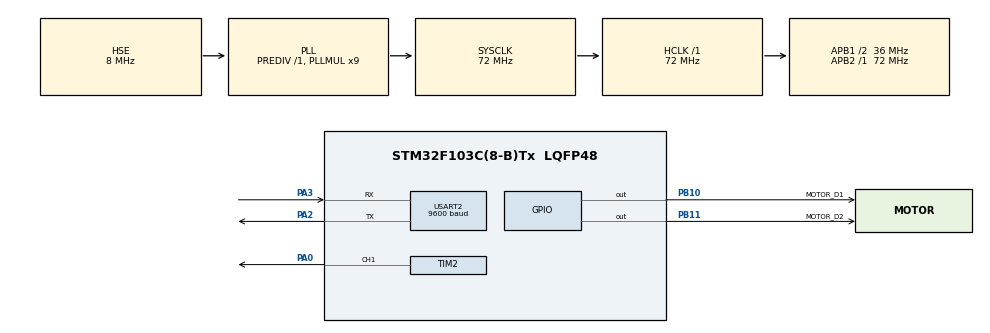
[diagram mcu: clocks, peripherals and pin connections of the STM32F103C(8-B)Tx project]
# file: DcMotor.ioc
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FREERTOS.Tasks01=UART,24,128,UART_T,Default,NULL,Dynamic,NULL,NULL;ADCRead,8,128,ADCRead_T,Default,NULL,Dynamic,NULL,NULL;Motor,10,128,Motor_T,Default,NULL,Dynamic,NULL,NULL
Mcu.Family=STM32F1
Mcu.Name=STM32F103C(8-B)Tx
Mcu.Package=LQFP48
NVIC.PriorityGroup=NVIC_PRIORITYGROUP_4
NVIC.TIM1_UP_IRQn=true\:15\:0\:false\:false\:true\:false\:false\:true\:true
NVIC.TimeBase=TIM1_UP_IRQn
NVIC.TimeBaseIP=TIM1
PA0-WKUP.Signal=S_TIM2_CH1_ETR
PA13.Mode=Serial_Wire
PA13.Signal=SYS_JTMS-SWDIO
PA14.Mode=Serial_Wire
PA14.Signal=SYS_JTCK-SWCLK
PA2.Mode=Asynchronous
PA2.Signal=USART2_TX
PA3.Mode=Asynchronous
PA3.Signal=USART2_RX
PB10.GPIO_Label=MOTOR_D1
PB10.Signal=GPIO_Output
PB11.GPIO_Label=MOTOR_D2
PB11.Signal=GPIO_Output
PD0-OSC_IN.Mode=HSE-External-Oscillator
PD0-OSC_IN.Signal=RCC_OSC_IN
PD1-OSC_OUT.Mode=HSE-External-Oscillator
PD1-OSC_OUT.Signal=RCC_OSC_OUT
ProjectManager.HeapSize=0x200
ProjectManager.StackSize=0x400
ProjectManager.TargetToolchain=STM32CubeIDE
RCC.AHBFreq_Value=72000000
RCC.APB1CLKDivider=RCC_HCLK_DIV2
RCC.APB1Freq_Value=36000000
RCC.APB1TimFreq_Value=72000000
RCC.APB2Freq_Value=72000000
RCC.APB2TimFreq_Value=72000000
RCC.HCLKFreq_Value=72000000
RCC.PLLMUL=RCC_PLL_MUL9
RCC.PLLSourceVirtual=RCC_PLLSOURCE_HSE
RCC.SYSCLKFreq_VALUE=72000000
RCC.SYSCLKSource=RCC_SYSCLKSOURCE_PLLCLK
RCC.USBFreq_Value=72000000
SH.S_TIM2_CH1_ETR.0=TIM2_CH1,PWM Generation1 CH1
TIM2.Channel-PWM\ Generation1\ CH1=TIM_CHANNEL_1
TIM2.Period=100-1
TIM2.Prescaler=72-1
USART2.BaudRate=9600
USART2.VirtualMode=VM_ASYNC
VP_FREERTOS_VS_CMSIS_V2.Mode=CMSIS_V2
VP_SYS_VS_tim1.Mode=TIM1
VP_TIM2_VS_ClockSourceINT.Mode=Internal
board=custom

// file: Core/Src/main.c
/* USER CODE BEGIN Header */
/**
  ******************************************************************************
  * @file           : main.c
  * @brief          : Main program body
  ******************************************************************************
  * @attention
  *
  * Copyright (c) 2024 STMicroelectronics.
  * All rights reserved.
  *
  * This software is licensed under terms that can be found in the LICENSE file
  * in the root directory of this software component.
  * If no LICENSE file comes with this software, it is provided AS-IS.
  *
  ******************************************************************************
  */
/* USER CODE END Header */
#include "main.h"
#include "cmsis_os.h"
#include "tim.h"
#include "usart.h"
#include "gpio.h"

void SystemClock_Config(void);
void MX_FREERTOS_Init(void);

int main(void)
{

  /* MCU Configuration--------------------------------------------------------*/

  /* Reset of all peripherals, Initializes the Flash interface and the Systick. */
  HAL_Init();

  /* Configure the system clock */
  SystemClock_Config();

  /* Initialize all configured peripherals */
  MX_GPIO_Init();
  MX_USART2_UART_Init();
  MX_TIM2_Init();
  /* USER CODE BEGIN 2 */
  /*Start the timer */
   TIM2->CCR1 = 70;
    HAL_TIM_PWM_Start(&htim2,TIM_CHANNEL_1);

  /* USER CODE END 2 */

  /* Init scheduler */
  osKernelInitialize();

  /* Call init function for freertos objects (in cmsis_os2.c) */
  MX_FREERTOS_Init();

  /* Start scheduler */
  osKernelStart();

  /* We should never get here as control is now taken by the scheduler */

  /* Infinite loop */
  while (1)
  {

  }
}

void SystemClock_Config(void)
{
  RCC_OscInitTypeDef RCC_OscInitStruct = {0};
  RCC_ClkInitTypeDef RCC_ClkInitStruct = {0};

  /** Initializes the RCC Oscillators according to the specified parameters
  * in the RCC_OscInitTypeDef structure.
  */
  RCC_OscInitStruct.OscillatorType = RCC_OSCILLATORTYPE_HSE;
  RCC_OscInitStruct.HSEState = RCC_HSE_ON;
  RCC_OscInitStruct.HSEPredivValue = RCC_HSE_PREDIV_DIV1;
  RCC_OscInitStruct.HSIState = RCC_HSI_ON;
  RCC_OscInitStruct.PLL.PLLState = RCC_PLL_ON;
  RCC_OscInitStruct.PLL.PLLSource = RCC_PLLSOURCE_HSE;
  RCC_OscInitStruct.PLL.PLLMUL = RCC_PLL_MUL9;
  if (HAL_RCC_OscConfig(&RCC_OscInitStruct) != HAL_OK)
  {
    Error_Handler();
  }

  /** Initializes the CPU, AHB and APB buses clocks
  */
  RCC_ClkInitStruct.ClockType = RCC_CLOCKTYPE_HCLK|RCC_CLOCKTYPE_SYSCLK
                              |RCC_CLOCKTYPE_PCLK1|RCC_CLOCKTYPE_PCLK2;
  RCC_ClkInitStruct.SYSCLKSource = RCC_SYSCLKSOURCE_PLLCLK;
  RCC_ClkInitStruct.AHBCLKDivider = RCC_SYSCLK_DIV1;
  RCC_ClkInitStruct.APB1CLKDivider = RCC_HCLK_DIV2;
  RCC_ClkInitStruct.APB2CLKDivider = RCC_HCLK_DIV1;

  if (HAL_RCC_ClockConfig(&RCC_ClkInitStruct, FLASH_LATENCY_2) != HAL_OK)
  {
    Error_Handler();
  }
}

void HAL_TIM_PeriodElapsedCallback(TIM_HandleTypeDef *htim)
{
  if (htim->Instance == TIM1) {
    HAL_IncTick();
  }
}

void Error_Handler(void)
{
  __disable_irq();
  while (1)
  {
  }
}

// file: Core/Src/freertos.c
/* USER CODE BEGIN Header */
/**
  ******************************************************************************
  * File Name          : freertos.c
  * Description        : Code for freertos applications
  ******************************************************************************
  * @attention
  *
  * Copyright (c) 2024 STMicroelectronics.
  * All rights reserved.
  *
  * This software is licensed under terms that can be found in the LICENSE file
  * in the root directory of this software component.
  * If no LICENSE file comes with this software, it is provided AS-IS.
  *
  ******************************************************************************
  */
/* USER CODE END Header */

#include "FreeRTOS.h"
#include "task.h"
#include "main.h"
#include "cmsis_os.h"

/* USER CODE BEGIN Includes */
#include "Motor.h"
/* USER CODE END Includes */

/* Definitions for UART */
osThreadId_t UARTHandle;
const osThreadAttr_t UART_attributes = {
  .name = "UART",
  .stack_size = 128 * 4,
  .priority = (osPriority_t) osPriorityNormal,
};
/* Definitions for ADCRead */
osThreadId_t ADCReadHandle;
const osThreadAttr_t ADCRead_attributes = {
  .name = "ADCRead",
  .stack_size = 128 * 4,
  .priority = (osPriority_t) osPriorityLow,
};
/* Definitions for Motor */
osThreadId_t MotorHandle;
const osThreadAttr_t Motor_attributes = {
  .name = "Motor",
  .stack_size = 128 * 4,
  .priority = (osPriority_t) osPriorityLow2,
};

void UART_T(void *argument);
void ADCRead_T(void *argument);
void Motor_T(void *argument);

void MX_FREERTOS_Init(void); /* (MISRA C 2004 rule 8.1) */

void MX_FREERTOS_Init(void) {

  /* Create the thread(s) */
  /* creation of UART */
  UARTHandle = osThreadNew(UART_T, NULL, &UART_attributes);

  /* creation of ADCRead */
  ADCReadHandle = osThreadNew(ADCRead_T, NULL, &ADCRead_attributes);

  /* creation of Motor */
  MotorHandle = osThreadNew(Motor_T, NULL, &Motor_attributes);

}

void UART_T(void *argument)
{
  for(;;)
  {
    osDelay(1);
  }
}

void ADCRead_T(void *argument)
{
  for(;;)
  {
    osDelay(1);
  }
}

void Motor_T(void *argument)
{
  /* USER CODE BEGIN Motor_T */
  /* Infinite loop */
  for(;;)
  {
    /*the min speed the motor run with*/
    Motor_Set_Speed(65);
    Motor_Move_L();
    osDelay(1000);
    Motor_Stop();
    osDelay(1000);
    /*The other direction */
    Motor_Set_Speed(100);
    Motor_Move_R();
    osDelay(1000);
    Motor_Stop();
    osDelay(1000);
  }
  /* USER CODE END Motor_T */
}
